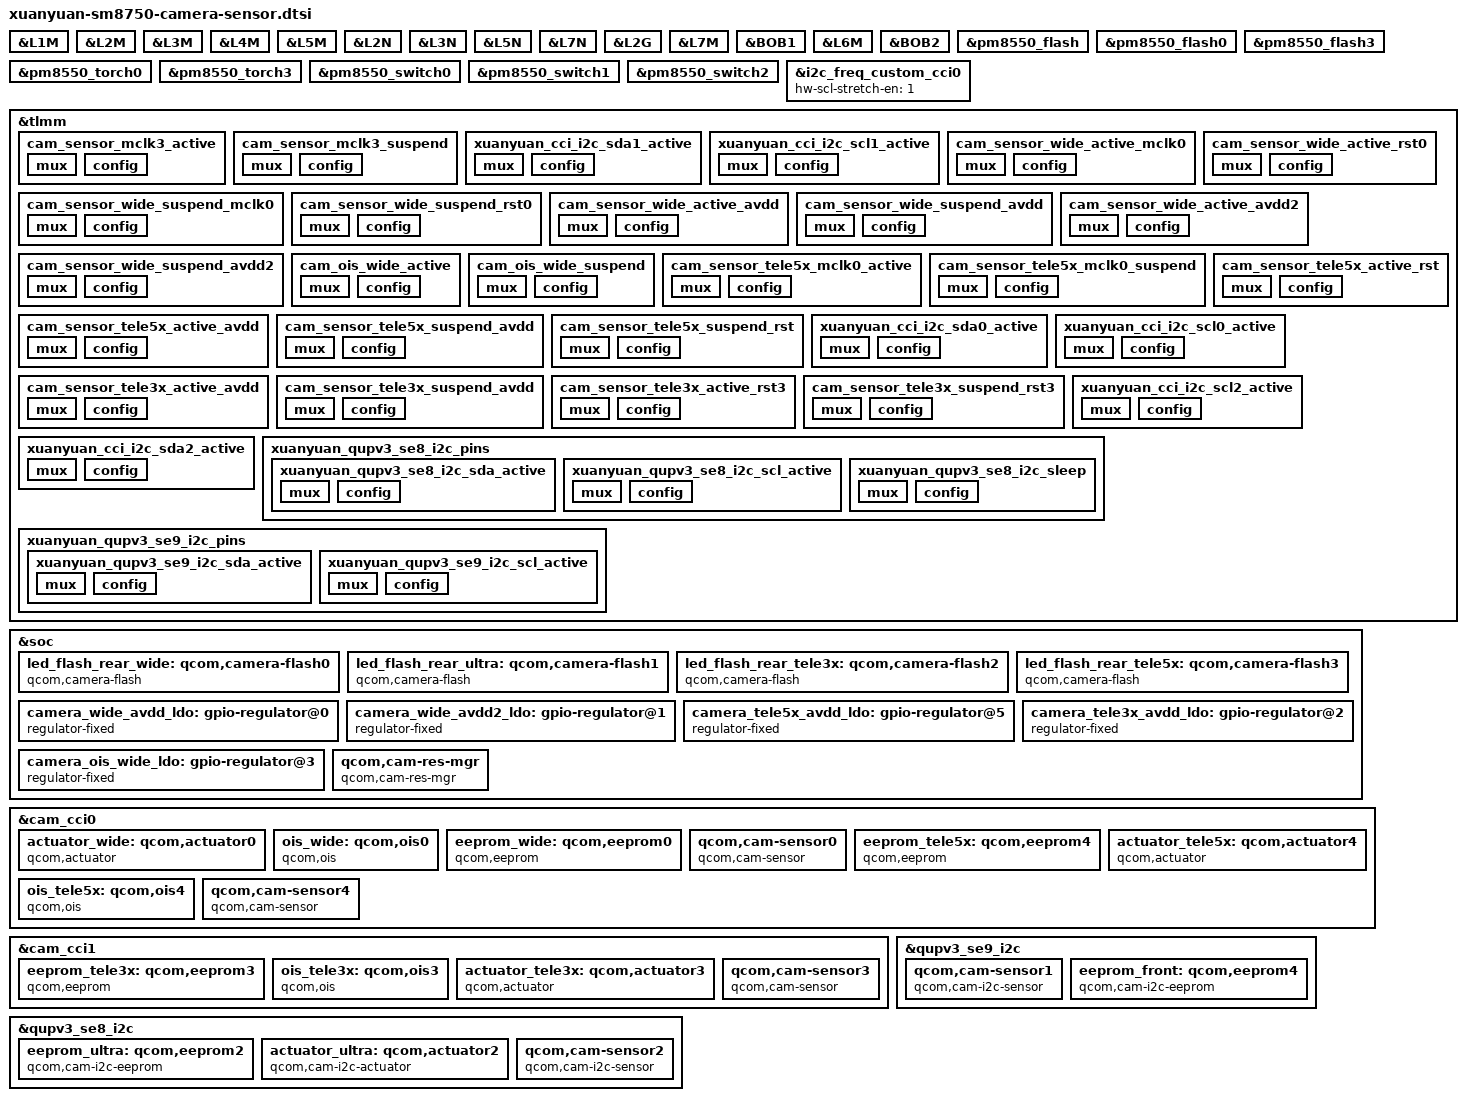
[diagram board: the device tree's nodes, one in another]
#include <dt-bindings/msm-camera.h>

&L1M {
	regulator-min-microvolt = <856000>;
	regulator-max-microvolt = <856000>;
	qcom,init-voltage = <856000>;
};

&L2M {
	regulator-min-microvolt = <1000000>;
	regulator-max-microvolt = <1000000>;
	qcom,init-voltage = <1000000>;
};

&L3M {
	regulator-min-microvolt = <2800000>;
	regulator-max-microvolt = <2800000>;
	qcom,init-voltage = <2800000>;
};

&L4M {
	regulator-min-microvolt = <2200000>;
	regulator-max-microvolt = <2200000>;
	qcom,init-voltage = <2200000>;
};

&L5M {
	regulator-min-microvolt = <3304000>;
	regulator-max-microvolt = <3304000>;
	qcom,init-voltage = <3304000>;
};

&L2N{
	regulator-min-microvolt = <904000>;
	regulator-max-microvolt = <904000>;
	qcom,init-voltage = <904000>;
};

&L3N {
	regulator-min-microvolt = <3304000>;
	regulator-max-microvolt = <3304000>;
	qcom,init-voltage = <3304000>;
};

&L5N {
	regulator-min-microvolt = <1800000>;
	regulator-max-microvolt = <1800000>;
	qcom,init-voltage = <1800000>;
};

&L7N {
	regulator-min-microvolt = <3304000>;
	regulator-max-microvolt = <3304000>;
	qcom,init-voltage = <3304000>;
};

&L2G {
	regulator-min-microvolt = <1104000>;
	regulator-max-microvolt = <1104000>;
	qcom,init-voltage = <1104000>;
};

&L7M {
	regulator-min-microvolt = <3304000>;
	regulator-max-microvolt = <3304000>;
	qcom,init-voltage = <3304000>;
};

&BOB1 {
	regulator-min-microvolt = <2704000>;
	regulator-max-microvolt = <3296000>;
};

&L6M {
	regulator-min-microvolt = <3304000>;
	regulator-max-microvolt = <3304000>;
	qcom,init-voltage = <3304000>;
};

&BOB2 {
	regulator-min-microvolt = <2704000>;
	regulator-max-microvolt = <3296000>;
};

&pm8550_flash {
	status = "ok";
};

&pm8550_flash0 {
	qcom,max-current-ma = <750>;
	qcom,duration-ms = <300>;
	xiaomi,max-duration-ms = <300>;
};

&pm8550_flash3 {
	qcom,max-current-ma = <750>;
	qcom,duration-ms = <300>;
	xiaomi,max-duration-ms = <300>;
};

&pm8550_torch0{
	qcom,max-current-ma = <100>;
	qcom,ires-ua = <5000>;
};

&pm8550_torch3{
	qcom,max-current-ma = <100>;
	qcom,ires-ua = <5000>;
};

&pm8550_switch0 {
	qcom,led-mask = <1>;
	qcom,symmetry-en;
};

&pm8550_switch1 {
	qcom,led-mask = <8>;
	qcom,symmetry-en;
};

&pm8550_switch2 {
	qcom,led-mask = <9>;
	qcom,symmetry-en;
};

&i2c_freq_custom_cci0{
	hw-scl-stretch-en = <1>;
};

&tlmm {
	cam_sensor_mclk3_active: cam_sensor_mclk3_active {
		/* MCLK3 */
		mux {
			pins = "gpio92";
			function = "cam_mclk";
		};

		config {
			pins = "gpio92";
			bias-disable; /* No PULL */
			drive-strength = <4>; /* 4 MA */
		};
	};

	cam_sensor_mclk3_suspend: cam_sensor_mclk3_suspend {
		/* MCLK3 */
		mux {
			pins = "gpio92";
			function = "cam_mclk";
		};

		config {
			pins = "gpio92";
			bias-pull-down; /* PULL DOWN */
			drive-strength = <4>; /* 4 MA */
		};
	};

	// wide
	xuanyuan_cci_i2c_sda1_active: xuanyuan_cci_i2c_sda1_active {
		mux {
			pins = "gpio115";
			function = "cci_i2c_sda1";
		};

		config {
			pins = "gpio115";
			bias-disable; /* NO PULL */
			drive-strength = <2>; /* 2 MA */
		};
	};

	xuanyuan_cci_i2c_scl1_active: xuanyuan_cci_i2c_scl1_active {
		mux {
			pins = "gpio116";
			function = "cci_i2c_scl1";
		};

		config {
			pins = "gpio116";
			bias-disable; /* NO PULL */
			drive-strength = <2>; /* 2 MA */
		};
	};

	cam_sensor_wide_active_mclk0: cam_sensor_wide_active_mclk0 {
		/* WIDE MCLK0 */
		mux {
			pins = "gpio90";
			function = "cam_mclk";
		};

		config {
			pins = "gpio90";
			bias-disable; /* No PULL */
			drive-strength = <4>; /* 4 MA */
		};
	};

	cam_sensor_wide_suspend_mclk0: cam_sensor_wide_suspend_mclk0 {
		/* WIDE MCLK0 */
		mux {
			pins = "gpio90";
			function = "cam_mclk";
		};

		config {
			pins = "gpio90";
			bias-pull-down; /* PULL DOWN */
			drive-strength = <4>; /* 4 MA */
		};
	};

	cam_sensor_wide_active_rst0: cam_sensor_wide_active_rst0 {
		mux {
			pins = "gpio188";
			function = "gpio";
		};

		config {
			pins = "gpio188";
			bias-disable; /* No PULL */
			drive-strength = <2>; /* 2 MA */
		};
	};

	cam_sensor_wide_suspend_rst0: cam_sensor_wide_suspend_rst0 {
		mux {
			pins = "gpio188";
			function = "gpio";
		};

		config {
			pins = "gpio188";
			bias-pull-down; /* PULL DOWN */
			drive-strength = <2>; /* 2 MA */
			output-low;
		};
	};

	cam_sensor_wide_active_avdd: cam_sensor_wide_active_avdd {
		mux {
			pins = "gpio127";
			function = "gpio";
		};

		config {
			pins = "gpio127";
			bias-disable; /* No PULL */
			drive-strength = <2>; /* 2 MA */
		};
	};

	cam_sensor_wide_suspend_avdd: cam_sensor_wide_suspend_avdd {
		mux {
			pins = "gpio127";
			function = "gpio";
		};

		config {
			pins = "gpio127";
			bias-pull-down; /* PULL DOWN */
			drive-strength = <2>; /* 2 MA */
			output-low;
		};
	};

	cam_sensor_wide_active_avdd2: cam_sensor_wide_active_avdd2 {
		mux {
			pins = "gpio119";
			function = "gpio";
		};

		config {
			pins = "gpio119";
			bias-disable; /* No PULL */
			drive-strength = <2>; /* 2 MA */
		};
	};

	cam_sensor_wide_suspend_avdd2: cam_sensor_wide_suspend_avdd2 {
		mux {
			pins = "gpio119";
			function = "gpio";
		};

		config {
			pins = "gpio119";
			bias-pull-down; /* PULL DOWN */
			drive-strength = <2>; /* 2 MA */
			output-low;
		};
	};

	cam_ois_wide_active: cam_ois_wide_active {
		mux {
			pins = "gpio208";
			function = "gpio";
		};

		config {
			pins = "gpio208";
			bias-disable; /* No PULL */
			drive-strength = <2>; /* 2 MA */
		};
	};

	cam_ois_wide_suspend: cam_ois_wide_suspend {
		mux {
			pins = "gpio208";
			function = "gpio";
		};

		config {
			pins = "gpio208";
			bias-pull-down; /* PULL DOWN */
			drive-strength = <2>; /* 2 MA */
			output-low;
		};
	};

    //Tele5X Mclk0
	cam_sensor_tele5x_mclk0_active: cam_sensor_tele5x_mclk0_active {
		/* MCLK0 */
		mux {
			pins = "gpio89";
			function = "cam_mclk";
		};

		config {
			pins = "gpio89";
			bias-disable; /* No PULL */
			drive-strength = <4>; /* 4 MA */
		};
	};

	cam_sensor_tele5x_mclk0_suspend: cam_sensor_tele5x_mclk0_suspend {
		/* MCLK0 */
		mux {
			pins = "gpio89";
			function = "cam_mclk";
		};

		config {
			pins = "gpio89";
			bias-pull-down; /* PULL DOWN */
			drive-strength = <4>; /* 4 MA */
		};
	};


	//Tele 5X avdd
	cam_sensor_tele5x_active_avdd: cam_sensor_tele5x_active_avdd {
		mux {
			pins = "gpio126";
			function = "gpio";
		};
		config {
			pins = "gpio126";
			bias-disable; /* No PULL */
			drive-strength = <2>; /* 2 MA */
		};
	};

	cam_sensor_tele5x_suspend_avdd: cam_sensor_tele5x_suspend_avdd {
		mux {
			pins = "gpio126";
			function = "gpio";
		};
		config {
			pins = "gpio126";
			bias-pull-down; /* PULL DOWN */
			drive-strength = <2>; /* 2 MA */
			output-low;
		};
	};
	//Tele5X RSN GPIO_213
	cam_sensor_tele5x_active_rst: cam_sensor_tele5x_active_rst {
		mux {
			pins = "gpio213";
			function = "gpio";
		};
		config {
			pins = "gpio213";
			bias-disable; /* No PULL */
			drive-strength = <2>; /* 2 MA */
		};
	};
	cam_sensor_tele5x_suspend_rst: cam_sensor_tele5x_suspend_rst {
		mux {
			pins = "gpio213";
			function = "gpio";
		};
		config {
			pins = "gpio213";
			bias-pull-down; /* PULL DOWN */
			drive-strength = <2>; /* 2 MA */
			output-low;
		};
	};

	xuanyuan_cci_i2c_sda0_active: xuanyuan_cci_i2c_sda0_active {
		mux {
			/* CLK, DATA */
			pins = "gpio113";
			function = "cci_i2c_sda0";
		};

		config {
			pins = "gpio113";
			bias-disable; /* NO PULL */
			drive-strength = <2>; /* 2 MA */
		};
	};

	xuanyuan_cci_i2c_scl0_active: xuanyuan_cci_i2c_scl0_active {
		mux {
			/* CLK, DATA */
			pins = "gpio114";
			function = "cci_i2c_scl0";
		};

		config {
			pins = "gpio114";
			bias-disable; /* NO PULL */
			drive-strength = <2>; /* 2 MA */
		};
	};

	cam_sensor_tele3x_active_avdd: cam_sensor_tele3x_active_avdd {
		mux {
			pins = "gpio129";
			function = "gpio";
		};

		config {
			pins = "gpio129";
			bias-disable; /* No PULL */
			drive-strength = <2>; /* 2 MA */
		};
	};

	cam_sensor_tele3x_suspend_avdd: cam_sensor_tele3x_suspend_avdd {
		mux {
			pins = "gpio129";
			function = "gpio";
		};

		config {
			pins = "gpio129";
			bias-pull-down; /* PULL DOWN */
			drive-strength = <2>; /* 2 MA */
			output-low;
		};
	};

	cam_sensor_tele3x_active_rst3: cam_sensor_tele3x_active_rst3 {
		mux {
			pins = "gpio197";
			function = "gpio";
		};

		config {
			pins = "gpio197";
			bias-disable; /* No PULL */
			drive-strength = <2>; /* 2 MA */
		};
	};

	cam_sensor_tele3x_suspend_rst3: cam_sensor_tele3x_suspend_rst3 {
		mux {
			pins = "gpio197";
			function = "gpio";
		};

		config {
			pins = "gpio197";
			bias-pull-down; /* PULL DOWN */
			drive-strength = <2>; /* 2 MA */
			output-low;
		};
	};

	xuanyuan_cci_i2c_scl2_active: xuanyuan_cci_i2c_scl2_active {
		mux {
			/* CLK, DATA */
			pins = "gpio118";
			function = "cci_i2c_scl2";
		};

		config {
			pins = "gpio118";
			bias-disable; /* NO PULL */
			drive-strength = <2>; /* 2 MA */
		};
	};

	xuanyuan_cci_i2c_sda2_active: xuanyuan_cci_i2c_sda2_active {
		mux {
			/* CLK, DATA */
			pins = "gpio117";
			function = "cci_i2c_sda2";
		};

		config {
			pins = "gpio117";
			bias-disable; /* NO PULL */
			drive-strength = <2>; /* 2 MA */
		};
	};

	xuanyuan_qupv3_se8_i2c_pins: xuanyuan_qupv3_se8_i2c_pins {
		xuanyuan_qupv3_se8_i2c_sda_active: xuanyuan_qupv3_se8_i2c_sda_active {
			mux {
				pins = "gpio0";
				function = "qup2_se0_l0";
			};

			config {
				pins = "gpio0";
				drive-strength = <2>;
				bias-disable;
				qcom,apps;
			};
		};

		xuanyuan_qupv3_se8_i2c_scl_active: xuanyuan_qupv3_se8_i2c_scl_active {
			mux {
				pins = "gpio1";
				function = "qup2_se0_l1";
			};

			config {
				pins = "gpio1";
				drive-strength = <2>;
				bias-disable;
				qcom,apps;
			};
		};

		xuanyuan_qupv3_se8_i2c_sleep: xuanyuan_qupv3_se8_i2c_sleep {
			mux {
				pins = "gpio0", "gpio1";
				function = "gpio";
			};

			config {
				pins = "gpio0", "gpio1";
				drive-strength = <2>;
				qcom,remote;
			};
		};
	};

	xuanyuan_qupv3_se9_i2c_pins: xuanyuan_qupv3_se9_i2c_pins {
		xuanyuan_qupv3_se9_i2c_sda_active: xuanyuan_qupv3_se9_i2c_sda_active {
			mux {
				pins = "gpio4";
				function = "qup2_se1_l0";
			};

			config {
				pins = "gpio4";
				drive-strength = <2>;
				bias-disable;
				qcom,apps;
			};
		};

		xuanyuan_qupv3_se9_i2c_scl_active: xuanyuan_qupv3_se9_i2c_scl_active {
			mux {
				pins = "gpio5";
				function = "qup2_se1_l1";
			};

			config {
				pins = "gpio5";
				drive-strength = <2>;
				bias-disable;
				qcom,apps;
			};
		};
        };
};


&soc {
	led_flash_rear_wide: qcom,camera-flash0 {
		cell-index = <0>;
		compatible = "qcom,camera-flash";
		flash-source = <&pm8550_flash0 &pm8550_flash3>;
		torch-source = <&pm8550_torch0 &pm8550_torch3>;
		switch-source = <&pm8550_switch2>;
		status = "ok";
	};

	led_flash_rear_ultra: qcom,camera-flash1 {
		cell-index = <1>;
		compatible = "qcom,camera-flash";
		flash-source = <&pm8550_flash0 &pm8550_flash3>;
		torch-source = <&pm8550_torch0 &pm8550_torch3>;
		switch-source = <&pm8550_switch2>;
		status = "ok";
	};

	led_flash_rear_tele3x: qcom,camera-flash2 {
		cell-index = <2>;
		compatible = "qcom,camera-flash";
		flash-source = <&pm8550_flash0 &pm8550_flash3>;
		torch-source = <&pm8550_torch0 &pm8550_torch3>;
		switch-source = <&pm8550_switch2>;
		status = "ok";
	};

	led_flash_rear_tele5x: qcom,camera-flash3 {
		cell-index = <3>;
		compatible = "qcom,camera-flash";
		flash-source = <&pm8550_flash0 &pm8550_flash3>;
		torch-source = <&pm8550_torch0 &pm8550_torch3>;
		switch-source = <&pm8550_switch2>;
		status = "ok";
	};

	camera_wide_avdd_ldo: gpio-regulator@0 {
		compatible = "regulator-fixed";
		reg = <0x00 0x00>;
		regulator-name = "camera_wide_avdd_ldo";
		regulator-min-microvolt = <2900000>;
		regulator-max-microvolt = <2900000>;
		regulator-enable-ramp-delay = <100>;
		enable-active-high;
		gpio = <&tlmm 127 0>;
		pinctrl-names = "wide_avdd_active", "wide_avdd_suspend";
		pinctrl-0 = <&cam_sensor_wide_active_avdd
					 &cam_sensor_wide_suspend_avdd>;
	};

	camera_wide_avdd2_ldo: gpio-regulator@1 {
		compatible = "regulator-fixed";
		reg = <0x01 0x00>;
		regulator-name = "camera_wide_avdd2_ldo";
		regulator-min-microvolt = <1800000>;
		regulator-max-microvolt = <1800000>;
		regulator-enable-ramp-delay = <100>;
		enable-active-high;
		gpio = <&tlmm 119 0>;
		pinctrl-names = "wide_avdd2_active", "wide_avdd2_suspend";
		pinctrl-0 = <&cam_sensor_wide_active_avdd2
					 &cam_sensor_wide_suspend_avdd2>;
	};

	//Tele5X avdd
	camera_tele5x_avdd_ldo: gpio-regulator@5 {
		compatible = "regulator-fixed";
		reg = <0x05 0x00>;
		regulator-name = "camera_tele5x_avdd_ldo";
		regulator-min-microvolt = <2200000>;
		regulator-max-microvolt = <2200000>;
		regulator-enable-ramp-delay = <100>;
		enable-active-high;
		gpio = <&tlmm 126 0>;
		pinctrl-names = "tele5x_avdd_active", "tele5x_avdd_suspend";
		pinctrl-0 = <&cam_sensor_tele5x_active_avdd
					 &cam_sensor_tele5x_suspend_avdd>;
	};


	camera_tele3x_avdd_ldo: gpio-regulator@2 {
		compatible = "regulator-fixed";
		reg = <0x02 0x00>;
		regulator-name = "camera_tele3x_avdd_ldo";
		regulator-min-microvolt = <2800000>;
		regulator-max-microvolt = <2800000>;
		regulator-enable-ramp-delay = <100>;
		enable-active-high;
		gpio = <&tlmm 129 0>;
		pinctrl-names = "tele3x_avdd_active", "tele3x_avdd_suspend";
		pinctrl-0 = <&cam_sensor_tele3x_active_avdd
					 &cam_sensor_tele3x_suspend_avdd>;
	};

	camera_ois_wide_ldo: gpio-regulator@3 {
		compatible = "regulator-fixed";
		reg = <0x03 0x00>;
		regulator-name = "camera_ois_wide_ldo";
		regulator-min-microvolt = <5000000>;
		regulator-max-microvolt = <5000000>;
		regulator-enable-ramp-delay = <100>;
		enable-active-high;
		gpio = <&tlmm 208 0>;
		pinctrl-names = "ois_wide_active", "ois_wide_suspend";
		pinctrl-0 = <&cam_ois_wide_active
					 &cam_ois_wide_suspend>;
	};

	qcom,cam-res-mgr {
		compatible = "qcom,cam-res-mgr";
		gpios-shared-pinctrl = <602 700 604 709  601 725>;
		shared-pctrl-gpio-names = "cam_wide", "cam_wide", "cam_tele3x", "cam_tele3x", "cam_tele5x", "cam_tele5x";
		pinctrl-names = "cam_wide_active", "cam_wide_suspend", "cam_tele3x_active", "cam_tele3x_suspend", "cam_tele5x_active", "cam_tele5x_suspend";
		pinctrl-0 = <&cam_sensor_wide_active_mclk0
					&cam_sensor_wide_active_rst0>;
		pinctrl-1 = <&cam_sensor_wide_suspend_mclk0
					&cam_sensor_wide_suspend_rst0>;
		pinctrl-2 = <&cam_sensor_mclk3_active
					&cam_sensor_tele3x_active_rst3>;
		pinctrl-3 = <&cam_sensor_mclk3_suspend
					&cam_sensor_tele3x_suspend_rst3>;
		pinctrl-4 = <&cam_sensor_tele5x_mclk0_active
		             &cam_sensor_tele5x_active_rst>;
		pinctrl-5 = <&cam_sensor_tele5x_mclk0_suspend
		             &cam_sensor_tele5x_suspend_rst>;
		status = "ok";
	};
};

&cam_cci0 {
	pinctrl-0 = <&xuanyuan_cci_i2c_scl0_active &xuanyuan_cci_i2c_sda0_active>;
	pinctrl-2 = <&xuanyuan_cci_i2c_scl1_active &xuanyuan_cci_i2c_sda1_active>;

	// wide actuator
	actuator_wide: qcom,actuator0 {
		cell-index = <0>;
		compatible = "qcom,actuator";
		cam_vaf-supply = <&L5M>;
		cam_vio-supply = <&L5N>;
		regulator-names = "cam_vaf", "cam_vio";
		rgltr-cntrl-support;
		rgltr-min-voltage = <3304000 1800000>;
		rgltr-max-voltage = <3304000 1800000>;
		rgltr-load-current = <150000 150000>;
		cci-master = <CCI_MASTER_1>;
		status = "ok";
	};

	// wide ois
	ois_wide: qcom,ois0 {
		cell-index = <0>;
		compatible = "qcom,ois";
		cam_vana-supply = <&camera_wide_avdd_ldo>;
		cam_vio-supply = <&L5N>;
		cam_vdig-supply = <&L1M>;
		cam_v_custom1-supply = <&camera_wide_avdd2_ldo>;
		cam_v_custom2-supply = <&camera_ois_wide_ldo>;
		cam_clk-supply = <&cam_cc_titan_top_gdsc>;
		cam_vaf-supply = <&L5M>;
		regulator-names = "cam_vana", "cam_vio", "cam_vdig",
					"cam_v_custom1", "cam_clk", "cam_vaf", "cam_v_custom2";
		rgltr-cntrl-support;
		rgltr-min-voltage = <2900000 1800000 856000 1800000 0 3304000 5000000>;
		rgltr-max-voltage = <2900000 1800000 856000 1800000 0 3304000 5000000>;
		rgltr-load-current = <150000 150000 150000 150000 0 150000 150000>;
		gpio-no-mux = <0>;
		use-shared-clk;
		gpios = <&tlmm 90 0>, <&tlmm 188 0>;
		gpio-reset = <1>;
		gpio-req-tbl-num = <0 1>;
		gpio-req-tbl-flags = <1 0>;
		gpio-req-tbl-label = "CAMIF_MCLK1", "CAM_RESET1";
		cci-master = <CCI_MASTER_1>;
		clocks = <&cambistmclkcc CAM_BIST_MCLK_CC_MCLK1_CLK>;
		clock-names = "cam_clk";
		clock-cntl-level = "nominal";
		clock-rates = <19200000>;
		status = "ok";
	};

	// wide eeprom
	eeprom_wide: qcom,eeprom0 {
		cell-index = <0>;
		compatible = "qcom,eeprom";
		cam_vana-supply = <&camera_wide_avdd_ldo>;
		cam_vio-supply = <&L5N>;
		cam_vdig-supply = <&L1M>;
		cam_v_custom1-supply = <&camera_wide_avdd2_ldo>;
		cam_clk-supply = <&cam_cc_titan_top_gdsc>;
		regulator-names = "cam_vana", "cam_vio", "cam_vdig",
					"cam_v_custom1", "cam_clk";
		rgltr-cntrl-support;
		rgltr-min-voltage = <2900000 1800000 856000 1800000 0>;
		rgltr-max-voltage = <2900000 1800000 856000 1800000 0>;
		rgltr-load-current = <150000 150000 150000 150000 0>;
		gpio-no-mux = <0>;
		use-shared-clk;
		gpios = <&tlmm 90 0>, <&tlmm 188 0>;
		gpio-reset = <1>;
		gpio-req-tbl-num = <0 1>;
		gpio-req-tbl-flags = <1 0>;
		gpio-req-tbl-label = "CAMIF_MCLK1", "CAM_RESET1";
		cci-master = <CCI_MASTER_1>;
		clocks = <&cambistmclkcc CAM_BIST_MCLK_CC_MCLK1_CLK>;
		clock-names = "cam_clk";
		clock-cntl-level = "nominal";
		clock-rates = <19200000>;
		status = "ok";
	};

	// wide sensor
	qcom,cam-sensor0 {
		cell-index = <0>;
		compatible = "qcom,cam-sensor";
		csiphy-sd-index = <1>;
		eeprom-src = <&eeprom_wide>;
		actuator-src = <&actuator_wide>;
		ois-src = <&ois_wide>;
		led-flash-src = <&led_flash_rear_wide>;
		sensor-position-roll = <90>;
		sensor-position-pitch = <0>;
		sensor-position-yaw = <180>;
		cam_vana-supply = <&camera_wide_avdd_ldo>;
		cam_vio-supply = <&L5N>;
		cam_vdig-supply = <&L1M>;
		cam_v_custom1-supply = <&camera_wide_avdd2_ldo>;
		cam_v_custom2-supply = <&camera_ois_wide_ldo>;
		cam_clk-supply = <&cam_cc_titan_top_gdsc>;
		cam_vaf-supply = <&L5M>;
		regulator-names = "cam_vana", "cam_vio", "cam_vdig",
					"cam_v_custom1", "cam_clk", "cam_vaf", "cam_v_custom2";
		rgltr-cntrl-support;
		rgltr-min-voltage = <2900000 1800000 856000 1800000 0 3304000 5000000>;
		rgltr-max-voltage = <2900000 1800000 856000 1800000 0 3304000 5000000>;
		rgltr-load-current = <150000 150000 150000 150000 0 150000 150000>;
		gpio-no-mux = <0>;
		use-shared-clk;
		gpios = <&tlmm 90 0>, <&tlmm 188 0>;
		gpio-reset = <1>;
		gpio-req-tbl-num = <0 1>;
		gpio-req-tbl-flags = <1 0>;
		gpio-req-tbl-label = "CAMIF_MCLK1", "CAM_RESET1";
		cci-master = <CCI_MASTER_1>;
		clocks = <&cambistmclkcc CAM_BIST_MCLK_CC_MCLK1_CLK>;
		clock-names = "cam_clk";
		clock-cntl-level = "nominal";
		clock-rates = <19200000>;
		status = "ok";
	};


	// Tele5X eeprom
	eeprom_tele5x: qcom,eeprom4 {
		cell-index = <4>;
		compatible = "qcom,eeprom";
		cam_vana-supply = <&camera_tele5x_avdd_ldo>;
		cam_vdig-supply = <&L2N>;  // Rewrite 904000,904mv
		cam_bob2-supply = <&BOB2>;
		cam_clk-supply  = <&cam_cc_titan_top_gdsc>;
		cam_bob-supply  = <&BOB1>;
		cam_v_custom1-supply = <&L3N>;// BOB1-> OIS 3.3V,[1800 3304]
		cam_vio-supply  = <&L5N>;      // Rewrite 1.8V
		cam_vaf-supply  = <&L7N>;      // BOB1-> AF ,3.3V,[3304,3304]
		regulator-names = "cam_vana", "cam_vio", "cam_vdig", "cam_bob2", "cam_clk",
		                  "cam_v_custom1","cam_vaf","cam_bob";
		rgltr-cntrl-support;
		rgltr-min-voltage  = <2200000 1800000 904000 2704000 0 3304000 3304000 2704000>;
		rgltr-max-voltage  = <2200000 1800000 904000 3296000 0 3304000 3304000 3296000>;
		rgltr-load-current = <150000 150000  150000 2000000 0 150000 150000 2000000> ;
		gpio-no-mux = <0>;
		use-shared-clk;
		gpios = <&tlmm 89 0>, <&tlmm 213 0>;
		gpio-reset = <1>;
		gpio-req-tbl-num = <0 1>;
		gpio-req-tbl-flags = <1 0>;
		gpio-req-tbl-label = "CAMIF_MCLK0", "CAM_RESET_TELE5X";
		cci-master = <CCI_MASTER_0>;
		clocks = <&cambistmclkcc CAM_BIST_MCLK_CC_MCLK0_CLK>;
		clock-names = "cam_clk";
		clock-cntl-level = "nominal";
		clock-rates = <19200000>;
		status = "ok";
	};

	// Tele5x Actuator
	actuator_tele5x: qcom,actuator4 {
		cell-index = <4>;
		compatible = "qcom,actuator";
		cam_v_custom1-supply = <&L3N>;//BOB1-> OIS 3.3V,[1800 3304]
		cam_vio-supply  = <&L5N>;//1.8V
		cam_vaf-supply  = <&L7N>;//BOB1-> AF ,3.3V,[3304,3304]
		cam_bob-supply  = <&BOB1>;
		regulator-names = "cam_v_custom1","cam_vio","cam_vaf","cam_bob";
		rgltr-cntrl-support;
		rgltr-min-voltage  = <3304000 1800000 3304000 2704000 >;
		rgltr-max-voltage  = <3304000 1800000 3304000 3296000 >;
		rgltr-load-current = <150000 150000  150000   2000000 >;
		cci-master = <CCI_MASTER_0>;
		status = "ok";
	};


	// Tele5x Ois
	ois_tele5x: qcom,ois4 {
		cell-index = <4>;
		compatible = "qcom,ois";
		cam_vana-supply = <&camera_tele5x_avdd_ldo>;
		cam_vdig-supply = <&L2N>;  // Rewrite 904000,904mv
		cam_bob2-supply = <&BOB2>;
		cam_clk-supply  = <&cam_cc_titan_top_gdsc>;
		cam_bob-supply  = <&BOB1>;
		cam_v_custom1-supply = <&L3N>; // BOB1-> OIS 3.3V,[1800 3304]
		cam_vio-supply  = <&L5N>;      // Rewrite 1.8V
		cam_vaf-supply  = <&L7N>;      // BOB1-> AF ,3.3V,[3304,3304]
		regulator-names = "cam_vana", "cam_vio", "cam_vdig", "cam_bob2", "cam_clk",
		                  "cam_v_custom1","cam_vaf","cam_bob";
		rgltr-cntrl-support;
		rgltr-min-voltage  = <2200000 1800000 904000 2704000 0 3304000 3304000 2704000>;
		rgltr-max-voltage  = <2200000 1800000 904000 3296000 0 3304000 3304000 3296000>;
		rgltr-load-current = <150000  150000  150000 2000000 0 150000   150000 2000000> ;
		gpio-no-mux = <0>;
		use-shared-clk;
		gpios = <&tlmm 89 0>, <&tlmm 213 0>;
		gpio-reset = <1>;
		gpio-req-tbl-num   = <0 1>;
		gpio-req-tbl-flags = <1 0>;
		gpio-req-tbl-label = "CAMIF_MCLK0", "CAM_RESET_TELE5X";
		cci-master = <CCI_MASTER_0>;
		clocks = <&cambistmclkcc CAM_BIST_MCLK_CC_MCLK0_CLK>;
		clock-names = "cam_clk";
		clock-cntl-level = "nominal";
		clock-rates = <19200000>;
		status = "ok";
	};


	// Tele5x sensor
	qcom,cam-sensor4 {
		cell-index = <4>;// be same with camera ID
		compatible = "qcom,cam-sensor";
		csiphy-sd-index = <5>; //CSI5
		led-flash-src = <&led_flash_rear_tele5x>;
		eeprom-src = <&eeprom_tele5x>;
		actuator-src = <&actuator_tele5x>;
		ois-src = <&ois_tele5x>;
		sensor-position-roll  = <90>;
		sensor-position-pitch = <0>;
		sensor-position-yaw   = <180>;
		cam_vana-supply = <&camera_tele5x_avdd_ldo>;
		cam_vio-supply  = <&L5N>; // Rewrite 1800000
		cam_vdig-supply = <&L2N>; //Rewrite 904000,904mv
		cam_bob2-supply = <&BOB2>;//
		cam_clk-supply  = <&cam_cc_titan_top_gdsc>;
		cam_bob-supply  = <&BOB1>;
		cam_v_custom1-supply = <&L3N>; //BOB1-> L3N OIS 3.3V,[1800 3304]
		cam_vaf-supply  = <&L7N>;      //BOB1-> L7N AF ,3.3V,[3304,3304]
		regulator-names = "cam_vana", "cam_vio", "cam_vdig", "cam_bob2", "cam_clk",
		                  "cam_v_custom1","cam_vaf","cam_bob";
		rgltr-cntrl-support;
		rgltr-min-voltage = <2200000 1800000 904000 2704000 0 3304000 3304000 2704000>;
		rgltr-max-voltage = <2200000 1800000 904000 3296000 0 3304000 3304000 3296000>;
		rgltr-load-current = <150000 150000  150000 2000000 0 150000 150000 2000000> ;
		gpio-no-mux = <0>;
		use-shared-clk;
		gpios = <&tlmm 89 0>, <&tlmm 213 0>;
		gpio-reset = <1>;
		gpio-req-tbl-num = <0 1>;
		gpio-req-tbl-flags = <1 0>;
		gpio-req-tbl-label = "CAMIF_MCLK0", "CAM_RESET_TELE5X";
		cci-master = <CCI_MASTER_0>;
		clocks = <&cambistmclkcc CAM_BIST_MCLK_CC_MCLK0_CLK>;
		clock-names = "cam_clk";
		clock-cntl-level = "nominal";
		clock-rates = <19200000>;
		status = "ok";
	};


};

&cam_cci1 {
	pinctrl-0 = <&xuanyuan_cci_i2c_scl2_active &xuanyuan_cci_i2c_sda2_active>;

	// tele3x eeprom
	eeprom_tele3x: qcom,eeprom3 {
		cell-index = <3>;
		compatible = "qcom,eeprom";
		cam_vana-supply = <&camera_tele3x_avdd_ldo>;
		cam_bob2-supply = <&BOB2>;
		cam_vio-supply = <&L5N>;
		cam_vdig-supply = <&L2G>;
		cam_v_custom1-supply = <&L7M>;
		cam_bob-supply = <&BOB1>;
		cam_clk-supply = <&cam_cc_titan_top_gdsc>;
		cam_vaf-supply = <&L6M>;
		regulator-names = "cam_vana", "cam_bob2", "cam_vio", "cam_vdig",
					"cam_v_custom1", "cam_bob" , "cam_clk", "cam_vaf";
		rgltr-cntrl-support;
		rgltr-min-voltage = <2800000 2704000 1800000 1104000  3304000 2704000 0 3304000>;
		rgltr-max-voltage = <2800000 3296000 1800000 1104000 3304000 3296000 0 3304000>;
		rgltr-load-current = <150000 2000000 150000 150000  150000 2000000 0 150000>;
		gpio-no-mux = <0>;
		use-shared-clk;
		gpios = <&tlmm 92 0>, <&tlmm 197 0>;
		gpio-reset = <1>;
		gpio-req-tbl-num = <0 1>;
		gpio-req-tbl-flags = <1 0>;
		gpio-req-tbl-label = "CAMIF_MCLK3", "CAM_RESET3";
		cci-master = <CCI_MASTER_0>;
		clocks = <&cambistmclkcc CAM_BIST_MCLK_CC_MCLK3_CLK>;
		clock-names = "cam_clk";
		clock-cntl-level = "nominal";
		clock-rates = <19200000>;
		status = "ok";
	};

	// tele3x ois
	ois_tele3x: qcom,ois3 {
		cell-index = <3>;
		compatible = "qcom,ois";
		cam_vana-supply = <&camera_tele3x_avdd_ldo>;
		cam_bob2-supply = <&BOB2>;
		cam_vio-supply = <&L5N>;
		cam_vdig-supply = <&L2G>;
		cam_v_custom1-supply = <&L7M>;
		cam_bob-supply = <&BOB1>;
		cam_clk-supply = <&cam_cc_titan_top_gdsc>;
		cam_vaf-supply = <&L6M>;
		regulator-names = "cam_vana", "cam_bob2", "cam_vio", "cam_vdig",
					"cam_v_custom1", "cam_bob" , "cam_clk", "cam_vaf";
		rgltr-cntrl-support;
		rgltr-min-voltage = <2800000 2704000 1800000 1104000  3304000 2704000 0 3304000>;
		rgltr-max-voltage = <2800000 3296000 1800000 1104000 3304000 3296000 0 3304000>;
		rgltr-load-current = <150000 2000000 150000 150000  150000 2000000 0 150000>;
		gpio-no-mux = <0>;
		use-shared-clk;
		gpios = <&tlmm 92 0>, <&tlmm 197 0>;
		gpio-reset = <1>;
		gpio-req-tbl-num = <0 1>;
		gpio-req-tbl-flags = <1 0>;
		gpio-req-tbl-label = "CAMIF_MCLK3", "CAM_RESET3";
		cci-master = <CCI_MASTER_0>;
		clocks = <&cambistmclkcc CAM_BIST_MCLK_CC_MCLK3_CLK>;
		clock-names = "cam_clk";
		clock-cntl-level = "nominal";
		clock-rates = <19200000>;
		status = "ok";
	};

	// tele3x actuator
	actuator_tele3x: qcom,actuator3 {
		cell-index = <3>;
		compatible = "qcom,actuator";
		cci-master = <CCI_MASTER_0>;
		cam_vaf-supply = <&L6M>;
		cam_vio-supply = <&L5N>;
		cam_bob-supply = <&BOB1>;
		regulator-names = "cam_vaf", "cam_vio", "cam_bob";
		rgltr-cntrl-support;
		rgltr-min-voltage = <3304000 1800000 2704000>;
		rgltr-max-voltage = <3304000 1800000 3296000>;
		rgltr-load-current = <150000 150000 2000000>;
	};

	// tele3x sensor
	qcom,cam-sensor3 {
		cell-index = <3>;
		compatible = "qcom,cam-sensor";
		csiphy-sd-index = <0>;
		eeprom-src = <&eeprom_tele3x>;
		actuator-src = <&actuator_tele3x>;
		ois-src = <&ois_tele3x>;
		led-flash-src = <&led_flash_rear_tele3x>;
		sensor-position-roll = <90>;
		sensor-position-pitch = <0>;
		sensor-position-yaw = <180>;
		cam_vana-supply = <&camera_tele3x_avdd_ldo>;
		cam_bob2-supply = <&BOB2>;
		cam_vio-supply = <&L5N>;
		cam_vdig-supply = <&L2G>;
		cam_v_custom1-supply = <&L7M>;
		cam_bob-supply = <&BOB1>;
		cam_clk-supply = <&cam_cc_titan_top_gdsc>;
		cam_vaf-supply = <&L6M>;
		regulator-names = "cam_vana", "cam_bob2", "cam_vio", "cam_vdig",
					"cam_v_custom1", "cam_bob" , "cam_clk", "cam_vaf";
		rgltr-cntrl-support;
		rgltr-min-voltage = <2800000 2704000 1800000 1104000  3304000 2704000 0 3304000>;
		rgltr-max-voltage = <2800000 3296000 1800000 1104000 3304000 3296000 0 3304000>;
		rgltr-load-current = <150000 2000000 150000 150000  150000 2000000 0 150000>;
		gpio-no-mux = <0>;
		use-shared-clk;
		gpios = <&tlmm 92 0>, <&tlmm 197 0>;
		gpio-reset = <1>;
		gpio-req-tbl-num = <0 1>;
		gpio-req-tbl-flags = <1 0>;
		gpio-req-tbl-label = "CAMIF_MCLK3", "CAM_RESET3";
		cci-master = <CCI_MASTER_0>;
		clocks = <&cambistmclkcc CAM_BIST_MCLK_CC_MCLK3_CLK>;
		clock-names = "cam_clk";
		clock-cntl-level = "nominal";
		clock-rates = <19200000>;
		status = "ok";
	};
};
&qupv3_se8_i2c {
	status = "ok";
	qcom,high-perf;
	qcom,clk-freq-out = <1000000>;
	qcom,pm-ctrl-client;
	pinctrl-0 = <&xuanyuan_qupv3_se8_i2c_sda_active>, <&xuanyuan_qupv3_se8_i2c_scl_active>;
	pinctrl-1 = <&xuanyuan_qupv3_se8_i2c_sleep>;
	dmas = <&gpi_dma2 0 0 3 1024 0>,
		<&gpi_dma2 1 0 3 1024 0>;

	eeprom_ultra: qcom,eeprom2 {
		cell-index = <2>;
		reg = <0x50>;
		compatible = "qcom,cam-i2c-eeprom";
		cam_vio-supply = <&L5N>;
		regulator-names = "cam_vio";
		rgltr-cntrl-support;
		rgltr-min-voltage = <1800000>;
		rgltr-max-voltage = <1800000>;
		rgltr-load-current = <150000>;
		status = "ok";
	};

	actuator_ultra: qcom,actuator2 {
		cell-index = <2>;
		reg = <0x0C>;
		compatible = "qcom,cam-i2c-actuator";
		cam_vaf-supply = <&L3M>;
		cam_vio-supply = <&L5N>;
		cam_bob2-supply = <&BOB2>;
		regulator-names = "cam_vaf", "cam_vio", "cam_bob2";
		rgltr-cntrl-support;
		rgltr-min-voltage = <2800000 1800000 2704000>;
		rgltr-max-voltage = <2800000 1800000 3296000>;
		rgltr-load-current = <150000 150000 2000000>;
		status = "ok";
	};

	qcom,cam-sensor2 {
		cell-index = <2>;
		reg = <0x3D>;
		compatible = "qcom,cam-i2c-sensor";
		csiphy-sd-index = <2>;
		led-flash-src = <&led_flash_rear_ultra>;
		sensor-position-roll = <90>;
		sensor-position-pitch = <0>;
		sensor-position-yaw = <180>;
		actuator-src = <&actuator_ultra>;
		eeprom-src = <&eeprom_ultra>;
		cam_vio-supply = <&L5N>;
		cam_vdig-supply = <&L2M>;
		cam_clk-supply = <&cam_cc_titan_top_gdsc>;
		cam_vana-supply = <&L4M>;
		cam_vaf-supply = <&L3M>;
		cam_bob2-supply = <&BOB2>;
		regulator-names = "cam_vio", "cam_vdig", "cam_clk",
			"cam_vana", "cam_vaf", "cam_bob2";
		rgltr-cntrl-support;
		aon-camera-id = <AON_CAM2>;
		rgltr-min-voltage = <1800000 1000000 0 2200000 2800000 2704000>;
		rgltr-max-voltage = <1800000 1000000 0 2200000 2800000 3296000>;
		rgltr-load-current = <150000 150000 0 150000 150000 2000000>;
		gpio-no-mux = <0>;
		pinctrl-names = "cam_default", "cam_suspend";
		pinctrl-0 = <&cam_sensor_mclk2_active
					&cam_sensor_active_rst2>;
		pinctrl-1 = <&cam_sensor_mclk2_suspend
					&cam_sensor_suspend_rst2>;
		gpios = <&tlmm 91 0>, <&tlmm 3 0>;
		gpio-reset = <1>;
		gpio-req-tbl-num = <0 1>;
		gpio-req-tbl-flags = <1 0>;
		gpio-req-tbl-label = "CAMUW_MCLK2", "CAMUW_RESET2";
		clocks = <&cambistmclkcc CAM_BIST_MCLK_CC_MCLK2_CLK>;
		clock-names = "cam_clk";
		clock-cntl-level = "nominal";
		clock-rates = <19200000>;
		status = "ok";
	};
};

&qupv3_se9_i2c {
	status = "ok";
	qcom,clk-freq-out = <1000000>;
	qcom,high-perf;
	qcom,pm-ctrl-client;
	pinctrl-0 = <&xuanyuan_qupv3_se9_i2c_scl_active>, <&xuanyuan_qupv3_se9_i2c_sda_active>;

	// Front Sensor
	qcom,cam-sensor1 {
		cell-index = <1>;
		reg = <0x10>;
		compatible = "qcom,cam-i2c-sensor";
		csiphy-sd-index = <4>;
		eeprom-src = <&eeprom_front>;
		sensor-position-roll = <270>;
		sensor-position-pitch = <0>;
		sensor-position-yaw = <0>;
		cam_vana-supply = <&L6N>;
		cam_vio-supply = <&L5N>;
		cam_vdig-supply = <&L1N>;
		cam_clk-supply = <&cam_cc_titan_top_gdsc>;
		cam_bob2-supply = <&BOB2>;
		regulator-names = "cam_vana", "cam_vio",
			"cam_vdig", "cam_clk", "cam_bob2";
		rgltr-cntrl-support;
		aon-camera-id = <AON_CAM1>;
		rgltr-min-voltage = <2800000 1800000 1104000 0 2704000>;
		rgltr-max-voltage = <2800000 1800000 1104000 0 3296000>;
		rgltr-load-current = <150000 150000 150000 0 2000000>;
		gpio-no-mux = <0>;
		pinctrl-names = "cam_default", "cam_suspend";
		pinctrl-0 = <&cam_sensor_mclk4_active
			&cam_sensor_active_rst4>;
		pinctrl-1 = <&cam_sensor_mclk4_suspend
			&cam_sensor_suspend_rst4>;
		gpios = <&tlmm 93 0>, <&tlmm 7 0>;
		gpio-reset = <1>;
		gpio-req-tbl-num = <0 1>;
		gpio-req-tbl-flags = <1 0>;
		gpio-req-tbl-label = "CAMIF_MCLK4", "CAM_RESET4";
		clocks = <&cambistmclkcc CAM_BIST_MCLK_CC_MCLK4_CLK>;
		clock-names = "cam_clk";
		clock-cntl-level = "nominal";
		clock-rates = <19200000>;
		status = "ok";
	};

	//front
	eeprom_front: qcom,eeprom4 {
		cell-index = <1>;
		reg = <0x51>;
		compatible = "qcom,cam-i2c-eeprom";
		cam_vio-supply = <&L5N>;
		regulator-names = "cam_vio";
		rgltr-cntrl-support;
		rgltr-min-voltage = <1800000>;
		rgltr-max-voltage = <1800000>;
		rgltr-load-current = <150000>;
		status = "ok";
	};
};
